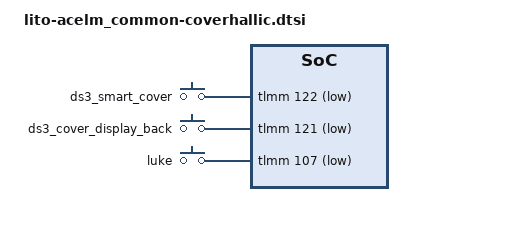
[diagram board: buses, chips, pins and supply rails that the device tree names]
// SPDX-License-Identifier: GPL-2.0-only
/*
 * Copyright (c) 2018-2019, The Linux Foundation. All rights reserved.
 */

&soc {
	gpio_keys {
		compatible = "gpio-keys";
		label = "gpio_keys";
		status = "okay";
		pinctrl_names = "default";
		pinctrl-0 = <&ds3_smartcover_gpio_default &ds3_cover_display_back_gpio_default &luke_gpio_default>;

		ds3_smart_cover {
			label = "ds3_smart_cover";
			gpios = <&tlmm 122 GPIO_ACTIVE_LOW>;
			linux,input-type = <5>;
			linux,code = <222>;
			gpio-key,wakeup;
			debounce-interval = <15>;
			linux,can-disable;
		};

		ds3_cover_display_back {
			label = "ds3_cover_display_back";
			gpios = <&tlmm 121 GPIO_ACTIVE_LOW>;
			linux,input-type = <5>;
			linux,code = <222>;
			gpio-key,wakeup;
			debounce-interval = <15>;
			linux,can-disable;
		};

		luke {
			label = "luke";
			gpios = <&tlmm 107 GPIO_ACTIVE_LOW>;
			linux,input-type = <5>;
			linux,code = <222>;
			gpio-key,wakeup;
			debounce-interval = <200>;
		};
	};
};
